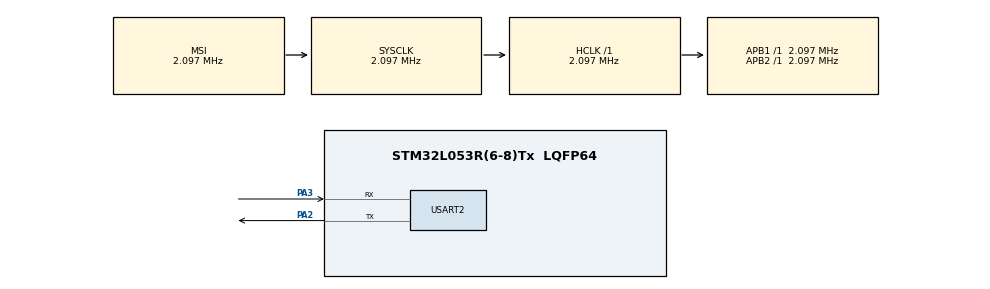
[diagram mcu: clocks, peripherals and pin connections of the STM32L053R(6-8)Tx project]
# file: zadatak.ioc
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Mcu.Family=STM32L0
Mcu.Name=STM32L053R(6-8)Tx
Mcu.Package=LQFP64
PA13.Mode=Serial_Wire
PA13.Signal=SYS_SWDIO
PA14.Mode=Serial_Wire
PA14.Signal=SYS_SWCLK
PA2.Mode=Asynchronous
PA2.Signal=USART2_TX
PA3.Mode=Asynchronous
PA3.Signal=USART2_RX
PC14-OSC32_IN.Mode=LSE-External-Oscillator
PC14-OSC32_IN.Signal=RCC_OSC32_IN
PC15-OSC32_OUT.Mode=LSE-External-Oscillator
PC15-OSC32_OUT.Signal=RCC_OSC32_OUT
PH0-OSC_IN.Mode=HSE-External-Oscillator
PH0-OSC_IN.Signal=RCC_OSC_IN
PH1-OSC_OUT.Mode=HSE-External-Oscillator
PH1-OSC_OUT.Signal=RCC_OSC_OUT
ProjectManager.HeapSize=0x200
ProjectManager.StackSize=0x400
ProjectManager.TargetToolchain=STM32CubeIDE
RCC.AHBFreq_Value=2097000
RCC.APB1Freq_Value=2097000
RCC.APB1TimFreq_Value=2097000
RCC.APB2Freq_Value=2097000
RCC.APB2TimFreq_Value=2097000
RCC.HCLKFreq_Value=2097000
RCC.HSE_VALUE=8000000
RCC.HSI16_VALUE=16000000
RCC.HSI48_VALUE=48000000
RCC.HSI_VALUE=16000000
RCC.MSI_VALUE=2097000
RCC.RTCClockSelectionVirtual=RCC_RTCCLKSOURCE_LSE
RCC.SYSCLKFreq_VALUE=2097000
RCC.VCOOutputFreq_Value=48000000
USART2.VirtualMode-Asynchronous=VM_ASYNC
VP_RTC_VS_RTC_Activate.Mode=RTC_Enabled
VP_RTC_VS_RTC_Calendar.Mode=RTC_Calendar
board=custom

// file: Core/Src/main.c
/* USER CODE BEGIN Header */
/**
  ******************************************************************************
  * @file           : main.c
  * @brief          : Main program body
  ******************************************************************************
  * @attention
  *
  * Copyright (c) 2023 STMicroelectronics.
  * All rights reserved.
  *
  * This software is licensed under terms that can be found in the LICENSE file
  * in the root directory of this software component.
  * If no LICENSE file comes with this software, it is provided AS-IS.
  *
  ******************************************************************************
  */
/* USER CODE END Header */
#include "main.h"

/* USER CODE BEGIN Includes */
#include <stdio.h>
#include <string.h>
/* USER CODE END Includes */

/* USER CODE BEGIN PTD */
char time[30];
uint8_t uartrx[9] = "";
uint8_t buff[100] = "";
int h = -1, m = -1;
int previous_minutes;
uint8_t hours[2]={0};
uint8_t minutes[2]={0};
/* USER CODE END PTD */
RTC_TimeTypeDef sTime;
RTC_DateTypeDef sDate;

RTC_HandleTypeDef hrtc;

UART_HandleTypeDef huart2;

void SystemClock_Config(void);
static void MX_GPIO_Init(void);
static void MX_RTC_Init(void);
static void MX_USART2_UART_Init(void);
void setup_time(void);

int main(void)
{

  /* MCU Configuration--------------------------------------------------------*/

  /* Reset of all peripherals, Initializes the Flash interface and the Systick. */
  HAL_Init();

  /* Configure the system clock */
  SystemClock_Config();

  /* Initialize all configured peripherals */
  MX_GPIO_Init();
  MX_USART2_UART_Init();
  setup_time();
  /* USER CODE BEGIN 2 */
  previous_minutes = sTime.Minutes;
  /* USER CODE END 2 */

  /* Infinite loop */
  while (1)
  {
HAL_RTC_GetDate(&hrtc, &sDate, RTC_FORMAT_BIN);
HAL_RTC_GetTime(&hrtc, &sTime, RTC_FORMAT_BIN);

sprintf(time, "Time: %02d:%02d:%02d\n",sTime.Hours,sTime.Minutes,sTime.Seconds);
if(sTime.Minutes != previous_minutes){
HAL_UART_Transmit(&huart2, (uint8_t *)time, strlen(time), 25);
previous_minutes = sTime.Minutes;
}
HAL_UART_Receive(&huart2, uartrx, 11, 100);
if(strcmp(uartrx, "SHOW CLOCK\n") == 0){		//ako se posalje SHOW CLOCK ponovno pokreni postavljanje vremena
	HAL_UART_Transmit(&huart2, (uint8_t *)time, strlen(time), 25);
	HAL_UART_Receive(&huart2, buff, 100, 100);
}
if(strcmp(uartrx, "SETUP TIME\n") == 0){		//ako se posalje SETUP TIME ponovno pokreni postavljanje vremena
	m = -1;
	setup_time();
	HAL_UART_Receive(&huart2, buff, 100, 100);
}
strcpy(uartrx, "");
  }
}
void setup_time(){
while(h < 0 || h >35 || m<0 || m > 89){
	  HAL_UART_Transmit(&huart2, "Unesi sate\n", 11, 25);
	  HAL_UART_Receive(&huart2, hours, 2, 10000);
	   h = (int*)strtol(hours, NULL, 16);
	   HAL_UART_Receive(&huart2, buff, 1, 10);

	   HAL_UART_Transmit(&huart2, "Unesi minute\n", 13, 25);
	  HAL_UART_Receive(&huart2, minutes, 2, 10000);
	  HAL_UART_Receive(&huart2, buff, 100, 10);
	  m = (int*)strtol(minutes, NULL, 16);
	MX_RTC_Init();
}
}

void SystemClock_Config(void)
{
  RCC_OscInitTypeDef RCC_OscInitStruct = {0};
  RCC_ClkInitTypeDef RCC_ClkInitStruct = {0};
  RCC_PeriphCLKInitTypeDef PeriphClkInit = {0};

  /** Configure the main internal regulator output voltage
  */
  __HAL_PWR_VOLTAGESCALING_CONFIG(PWR_REGULATOR_VOLTAGE_SCALE1);

  /** Initializes the RCC Oscillators according to the specified parameters
  * in the RCC_OscInitTypeDef structure.
  */
  RCC_OscInitStruct.OscillatorType = RCC_OSCILLATORTYPE_LSE|RCC_OSCILLATORTYPE_MSI;
  RCC_OscInitStruct.LSEState = RCC_LSE_ON;
  RCC_OscInitStruct.MSIState = RCC_MSI_ON;
  RCC_OscInitStruct.MSICalibrationValue = 0;
  RCC_OscInitStruct.MSIClockRange = RCC_MSIRANGE_5;
  RCC_OscInitStruct.PLL.PLLState = RCC_PLL_NONE;
  if (HAL_RCC_OscConfig(&RCC_OscInitStruct) != HAL_OK)
  {
    Error_Handler();
  }

  /** Initializes the CPU, AHB and APB buses clocks
  */
  RCC_ClkInitStruct.ClockType = RCC_CLOCKTYPE_HCLK|RCC_CLOCKTYPE_SYSCLK
                              |RCC_CLOCKTYPE_PCLK1|RCC_CLOCKTYPE_PCLK2;
  RCC_ClkInitStruct.SYSCLKSource = RCC_SYSCLKSOURCE_MSI;
  RCC_ClkInitStruct.AHBCLKDivider = RCC_SYSCLK_DIV1;
  RCC_ClkInitStruct.APB1CLKDivider = RCC_HCLK_DIV1;
  RCC_ClkInitStruct.APB2CLKDivider = RCC_HCLK_DIV1;

  if (HAL_RCC_ClockConfig(&RCC_ClkInitStruct, FLASH_LATENCY_0) != HAL_OK)
  {
    Error_Handler();
  }
  PeriphClkInit.PeriphClockSelection = RCC_PERIPHCLK_USART2|RCC_PERIPHCLK_RTC;
  PeriphClkInit.Usart2ClockSelection = RCC_USART2CLKSOURCE_PCLK1;
  PeriphClkInit.RTCClockSelection = RCC_RTCCLKSOURCE_LSE;
  if (HAL_RCCEx_PeriphCLKConfig(&PeriphClkInit) != HAL_OK)
  {
    Error_Handler();
  }
}

static void MX_RTC_Init(void)
{

  RTC_TimeTypeDef sTime = {0};
  RTC_DateTypeDef sDate = {0};

  /** Initialize RTC Only
  */
  hrtc.Instance = RTC;
  hrtc.Init.HourFormat = RTC_HOURFORMAT_24;
  hrtc.Init.AsynchPrediv = 127;
  hrtc.Init.SynchPrediv = 255;
  hrtc.Init.OutPut = RTC_OUTPUT_DISABLE;
  hrtc.Init.OutPutRemap = RTC_OUTPUT_REMAP_NONE;
  hrtc.Init.OutPutPolarity = RTC_OUTPUT_POLARITY_HIGH;
  hrtc.Init.OutPutType = RTC_OUTPUT_TYPE_OPENDRAIN;
  if (HAL_RTC_Init(&hrtc) != HAL_OK)
  {
    Error_Handler();
  }

  /** Initialize RTC and set the Time and Date
  */

  sTime.Hours = h;
  sTime.Minutes = m;
  sTime.Seconds = 0x00;
  sTime.DayLightSaving = RTC_DAYLIGHTSAVING_NONE;
  sTime.StoreOperation = RTC_STOREOPERATION_RESET;
  if (HAL_RTC_SetTime(&hrtc, &sTime, RTC_FORMAT_BCD) != HAL_OK)
  {
    Error_Handler();
  }

  if (HAL_RTC_SetDate(&hrtc, &sDate, RTC_FORMAT_BCD) != HAL_OK)
  {
    Error_Handler();
  }

}

static void MX_USART2_UART_Init(void)
{

  huart2.Instance = USART2;
  huart2.Init.BaudRate = 115200;
  huart2.Init.WordLength = UART_WORDLENGTH_8B;
  huart2.Init.StopBits = UART_STOPBITS_1;
  huart2.Init.Parity = UART_PARITY_NONE;
  huart2.Init.Mode = UART_MODE_TX_RX;
  huart2.Init.HwFlowCtl = UART_HWCONTROL_NONE;
  huart2.Init.OverSampling = UART_OVERSAMPLING_16;
  huart2.Init.OneBitSampling = UART_ONE_BIT_SAMPLE_DISABLE;
  huart2.AdvancedInit.AdvFeatureInit = UART_ADVFEATURE_NO_INIT;
  if (HAL_UART_Init(&huart2) != HAL_OK)
  {
    Error_Handler();
  }

}

static void MX_GPIO_Init(void)
{

  /* GPIO Ports Clock Enable */
  __HAL_RCC_GPIOC_CLK_ENABLE();
  __HAL_RCC_GPIOH_CLK_ENABLE();
  __HAL_RCC_GPIOA_CLK_ENABLE();

}

void Error_Handler(void)
{
  __disable_irq();
  while (1)
  {
  }
}
